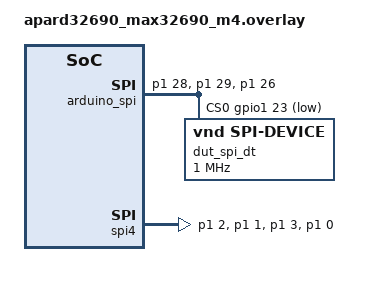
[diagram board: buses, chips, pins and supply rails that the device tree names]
/*
 * Copyright (c) 2023-2024 Analog Devices, Inc.
 *
 * SPDX-License-Identifier: Apache-2.0
 */

/*
 * Requires the following connections between the Uno(P5) and PMOD(P8) connectors
 * P1.26 - P1.03 - CLK
 * P1.28 - P1.02 - MISO
 * P1.29 - P1.01 - MOSI
 * P1.23 - P1.00 - CS
 */

/ {
	zephyr,user {
		peripheral-cs = <1>;
	};
};

&dma0 {
	status = "okay";
};

&arduino_spi {
	status = "okay";
	dmas = <&dma0 1 MAX32_DMA_SLOT_SPI1_TX>, <&dma0 2 MAX32_DMA_SLOT_SPI1_RX>;
	dma-names = "tx", "rx";
	pinctrl-0 = <&spi1a_miso_p1_28 &spi1a_mosi_p1_29 &spi1a_sck_p1_26>;
	cs-gpios = <&gpio1 23 (GPIO_ACTIVE_LOW | MAX32_GPIO_VSEL_VDDIOH)>;

	dut_spi_dt: test-spi-dev@0 {
		compatible = "vnd,spi-device";
		reg = <0>;
		spi-max-frequency = <DT_FREQ_M(1)>;
	};
};

dut_spis: &spi4 {
	pinctrl-0 = <&spi4a_miso_p1_2 &spi4a_mosi_p1_1 &spi4a_sck_p1_3
		     &spi4a_ss0_p1_0>;
	pinctrl-names = "default";

	status = "okay";
};
